VERSION ""

NS_ :

BS_:

BU_: Gateway_MQB XXX

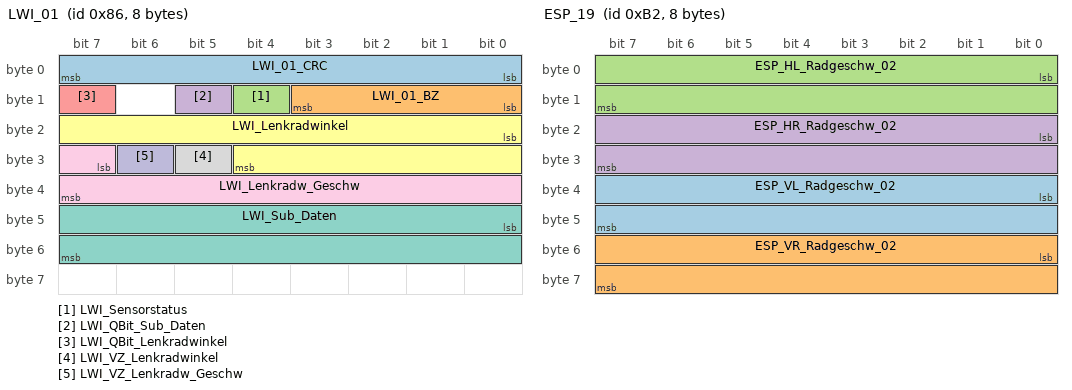
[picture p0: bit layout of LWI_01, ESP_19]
BO_ 134 LWI_01: 8 Gateway_MQB
 SG_ LWI_01_CRC : 0|8@1+ (1,0) [0|255] "" Airbag_MQB,Getriebe_DQ_Hybrid_MQB,Getriebe_DQ_MQB,Motor_Diesel_MQB,Motor_Hybrid_MQB,Motor_Otto_MQB
 SG_ LWI_01_BZ : 8|4@1+ (1,0) [0|15] "" Airbag_MQB,Getriebe_DQ_Hybrid_MQB,Getriebe_DQ_MQB,Motor_Diesel_MQB,Motor_Hybrid_MQB,Motor_Otto_MQB
 SG_ LWI_Sensorstatus : 12|1@1+ (1,0) [0|1] "" Airbag_MQB,Getriebe_DQ_Hybrid_MQB,Getriebe_DQ_MQB,Motor_Diesel_MQB,Motor_Hybrid_MQB,Motor_Otto_MQB
 SG_ LWI_QBit_Sub_Daten : 13|1@1+ (1,0) [0|1] "" Vector__XXX
 SG_ LWI_QBit_Lenkradwinkel : 15|1@1+ (1,0) [0|1] "" Airbag_MQB,Getriebe_DQ_Hybrid_MQB,Getriebe_DQ_MQB,Motor_Diesel_MQB,Motor_Hybrid_MQB,Motor_Otto_MQB
 SG_ LWI_Lenkradwinkel : 16|13@1+ (0.1,0) [0|800] "Unit_DegreOfArc" Airbag_MQB,Getriebe_DQ_Hybrid_MQB,Getriebe_DQ_MQB,Motor_Diesel_MQB,Motor_Hybrid_MQB,Motor_Otto_MQB
 SG_ LWI_Sub_Daten : 40|16@1+ (1,0) [0|65535] "" Vector__XXX
 SG_ LWI_VZ_Lenkradwinkel : 29|1@1+ (1,0) [0|1] "" Airbag_MQB,Getriebe_DQ_Hybrid_MQB,Getriebe_DQ_MQB,Motor_Diesel_MQB,Motor_Hybrid_MQB,Motor_Otto_MQB
 SG_ LWI_Lenkradw_Geschw : 31|9@1+ (5,0) [0|2500] "Unit_DegreOfArcPerSecon" Vector__XXX
 SG_ LWI_VZ_Lenkradw_Geschw : 30|1@1+ (1,0) [0|1] "" Vector__XXX

BO_ 178 ESP_19: 8 Gateway_MQB
 SG_ ESP_VL_Radgeschw_02 : 32|16@1+ (0.0075,0) [0|491.49] "Unit_KiloMeterPerHour" Airbag_MQB,Getriebe_DQ_Hybrid_MQB,Getriebe_DQ_MQB,Motor_Diesel_MQB,Motor_Hybrid_MQB,Motor_Otto_MQB
 SG_ ESP_VR_Radgeschw_02 : 48|16@1+ (0.0075,0) [0|491.49] "Unit_KiloMeterPerHour" Airbag_MQB,Getriebe_DQ_Hybrid_MQB,Getriebe_DQ_MQB,Motor_Diesel_MQB,Motor_Hybrid_MQB,Motor_Otto_MQB
 SG_ ESP_HL_Radgeschw_02 : 0|16@1+ (0.0075,0) [0|491.49] "Unit_KiloMeterPerHour" Airbag_MQB,Getriebe_DQ_Hybrid_MQB,Getriebe_DQ_MQB,Motor_Diesel_MQB,Motor_Hybrid_MQB,Motor_Otto_MQB
 SG_ ESP_HR_Radgeschw_02 : 16|16@1+ (0.0075,0) [0|491.49] "Unit_KiloMeterPerHour" Airbag_MQB,Getriebe_DQ_Hybrid_MQB,Getriebe_DQ_MQB,Motor_Diesel_MQB,Motor_Hybrid_MQB,Motor_Otto_MQB

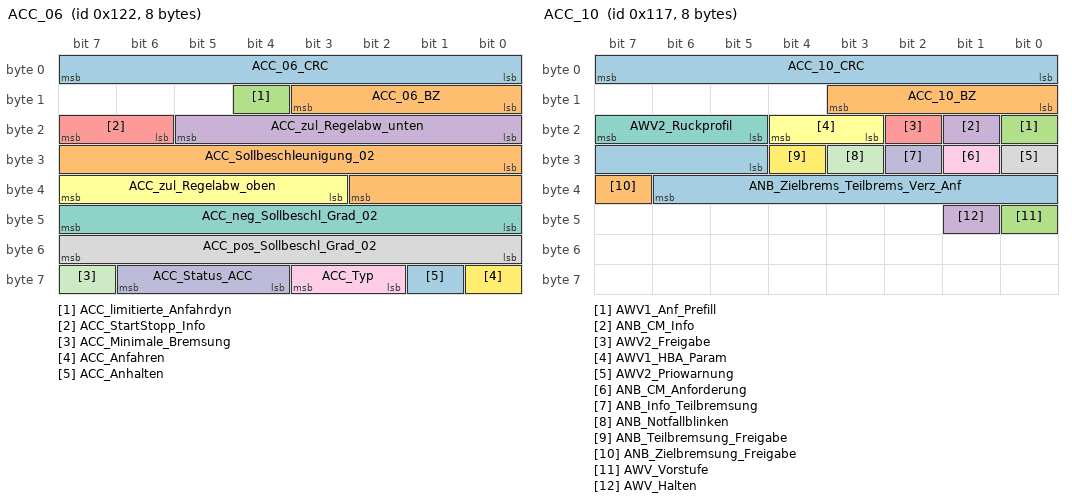
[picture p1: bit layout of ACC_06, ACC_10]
BO_ 290 ACC_06: 8 Gateway_MQB
 SG_ ACC_06_CRC : 0|8@1+ (1,0) [0|255] "" Getriebe_DQ_Hybrid_MQB,Getriebe_DQ_MQB,Motor_Diesel_MQB,Motor_Hybrid_MQB,Motor_Otto_MQB
 SG_ ACC_06_BZ : 8|4@1+ (1,0) [0|15] "" Getriebe_DQ_Hybrid_MQB,Getriebe_DQ_MQB,Motor_Diesel_MQB,Motor_Hybrid_MQB,Motor_Otto_MQB
 SG_ ACC_limitierte_Anfahrdyn : 12|1@1+ (1,0) [0|1] "" Motor_Diesel_MQB,Motor_Hybrid_MQB,Motor_Otto_MQB
 SG_ ACC_zul_Regelabw_unten : 16|6@1+ (0.024,0) [0|1.512] "Unit_MeterPerSeconSquar" Getriebe_DQ_Hybrid_MQB,Getriebe_DQ_MQB,Motor_Diesel_MQB,Motor_Hybrid_MQB,Motor_Otto_MQB
 SG_ ACC_StartStopp_Info : 22|2@1+ (1,0) [0|3] "" Motor_Diesel_MQB,Motor_Otto_MQB
 SG_ ACC_zul_Regelabw_oben : 35|5@1+ (0.0625,0) [0|1.9375] "Unit_MeterPerSeconSquar" Getriebe_DQ_Hybrid_MQB,Getriebe_DQ_MQB,Motor_Diesel_MQB,Motor_Hybrid_MQB,Motor_Otto_MQB
 SG_ ACC_neg_Sollbeschl_Grad_02 : 40|8@1+ (0.05,0) [0|12.75] "Unit_MeterPerCubicSecon" Motor_Diesel_MQB,Motor_Hybrid_MQB,Motor_Otto_MQB
 SG_ ACC_pos_Sollbeschl_Grad_02 : 48|8@1+ (0.05,0) [0|12.75] "Unit_MeterPerCubicSecon" Motor_Diesel_MQB,Motor_Hybrid_MQB,Motor_Otto_MQB
 SG_ ACC_Typ : 58|2@1+ (1,0) [0|3] "" Motor_Diesel_MQB,Motor_Hybrid_MQB,Motor_Otto_MQB
 SG_ ACC_Status_ACC : 60|3@1+ (1,0) [0|7] "" Getriebe_DQ_Hybrid_MQB,Getriebe_DQ_MQB,Motor_Diesel_MQB,Motor_Hybrid_MQB,Motor_Otto_MQB
 SG_ ACC_Minimale_Bremsung : 63|1@1+ (1,0) [0|1] "" Motor_Diesel_MQB,Motor_Hybrid_MQB,Motor_Otto_MQB
 SG_ ACC_Anfahren : 56|1@1+ (1,0) [0|1] "" Getriebe_DQ_Hybrid_MQB,Getriebe_DQ_MQB,Motor_Diesel_MQB,Motor_Hybrid_MQB,Motor_Otto_MQB
 SG_ ACC_Anhalten : 57|1@1+ (1,0) [0|1] "" Getriebe_DQ_Hybrid_MQB,Getriebe_DQ_MQB,Motor_Diesel_MQB,Motor_Hybrid_MQB,Motor_Otto_MQB
 SG_ ACC_Sollbeschleunigung_02 : 24|11@1+ (0.005,-7.22) [-7.22|3.005] "Unit_MeterPerSeconSquar" Getriebe_DQ_Hybrid_MQB,Getriebe_DQ_MQB,Motor_Diesel_MQB,Motor_Hybrid_MQB,Motor_Otto_MQB

BO_ 279 ACC_10: 8 Gateway_MQB
 SG_ ACC_10_CRC : 0|8@1+ (1,0) [0|255] "" Airbag_MQB
 SG_ ACC_10_BZ : 8|4@1+ (1,0) [0|15] "" Airbag_MQB
 SG_ AWV1_Anf_Prefill : 16|1@1+ (1,0) [0|1] "" Airbag_MQB
 SG_ ANB_CM_Info : 17|1@1+ (1,0) [0|1] "" Vector__XXX
 SG_ AWV2_Freigabe : 18|1@1+ (1,0) [0|1] "" Airbag_MQB
 SG_ AWV1_HBA_Param : 19|2@1+ (1,0) [0|3] "" Vector__XXX
 SG_ AWV2_Ruckprofil : 21|3@1+ (1,0) [0|7] "" Vector__XXX
 SG_ AWV2_Priowarnung : 24|1@1+ (1,0) [0|1] "" Vector__XXX
 SG_ ANB_CM_Anforderung : 25|1@1+ (1,0) [0|1] "" Airbag_MQB
 SG_ ANB_Info_Teilbremsung : 26|1@1+ (1,0) [0|1] "" Vector__XXX
 SG_ ANB_Notfallblinken : 27|1@1+ (1,0) [0|1] "" Vector__XXX
 SG_ ANB_Teilbremsung_Freigabe : 28|1@1+ (1,0) [0|1] "" Airbag_MQB
 SG_ ANB_Zielbrems_Teilbrems_Verz_Anf : 29|10@1+ (0.024,-20.016) [-20.016|4.536] "Unit_MeterPerSeconSquar" Airbag_MQB
 SG_ ANB_Zielbremsung_Freigabe : 39|1@1+ (1,0) [0|1] "" Airbag_MQB
 SG_ AWV_Vorstufe : 40|1@1+ (1,0) [0|1] "" Vector__XXX
 SG_ AWV_Halten : 41|1@1+ (1,0) [0|1] "" Vector__XXX

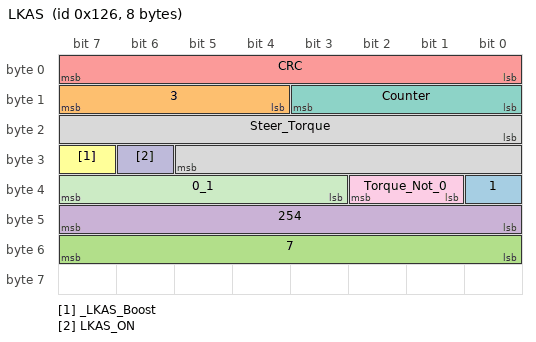
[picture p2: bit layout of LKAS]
BO_ 294 LKAS: 8 XXX
 SG_ 1 : 32|1@1+ (1,0) [0|3] "" XXX
 SG_ 3 : 15|4@0+ (1,0) [0|15] "" XXX
 SG_ 7 : 55|8@0+ (1,0) [0|255] "" XXX
 SG_ 254 : 47|8@0+ (1,0) [0|255] "" XXX
 SG_ CRC : 7|8@0+ (1,0) [0|255] "" XXX
 SG_ _LKAS_Boost : 31|1@0+ (1,0) [0|255] "" XXX
 SG_ Counter : 11|4@0+ (1,0) [0|255] "" XXX
 SG_ Steer_Torque : 16|14@1+ (1,0) [0|255] "" XXX
 SG_ Torque_Not_0 : 34|2@0+ (1,-1) [0|255] "" XXX
 SG_ LKAS_ON : 30|1@0+ (1,0) [0|3] "" XXX
 SG_ 0_1 : 39|5@0+ (1,0) [0|2047] "" XXX

CM_ SG_ 294 Steer_Torque "Stock limit 300.00";
CM_ SG_ 294 Torque_Not_0 "2 when torque is greater than 0";
